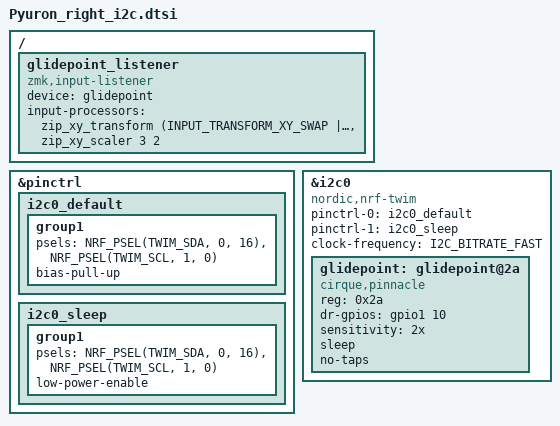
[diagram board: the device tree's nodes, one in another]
#include <input/processors.dtsi>
#include <dt-bindings/zmk/input_transform.h>
#include "Pyuron.dtsi"

&pinctrl {
    i2c0_default: i2c0_default {
        group1 {
            psels = <NRF_PSEL(TWIM_SDA, 0, 16)>,
                <NRF_PSEL(TWIM_SCL, 1, 0)>;
			bias-pull-up;
        };
    };

    i2c0_sleep: i2c0_sleep {
        group1 {
            psels = <NRF_PSEL(TWIM_SDA, 0, 16)>,
                <NRF_PSEL(TWIM_SCL, 1, 0)>;
            low-power-enable;
        };
    };
};

cirque_pinnacle_i2c: &i2c0 {
    compatible = "nordic,nrf-twim";
    pinctrl-0 = <&i2c0_default>;
    pinctrl-1 = <&i2c0_sleep>;
    pinctrl-names = "default", "sleep";
    clock-frequency = <I2C_BITRATE_FAST>;
};

// Enable custom i2c for the Right side

&cirque_pinnacle_i2c {
    status = "okay";

    glidepoint: glidepoint@2a {
        compatible = "cirque,pinnacle";
        reg = <0x2a>;
        status = "okay";
        // Pin marked as Serial in the Dilemma PCB (008/D0) is connected to the S pin in the TRRS footprint, 
        // so connecting this S pin to the DR pin in the Cirque, 
        // will make the MCU be notified when there is data ready in the cirque
        dr-gpios = <&gpio1 10 (GPIO_ACTIVE_HIGH)>;
        sensitivity = "2x";
        sleep; 
        no-taps;
    };
};

// Cirque Trackpad

&glidepoint {
	status = "okay";
};

// Cirque Trackpad, if the Left side is central, comment otherwise



// Cirque Trackpad, if the Right side is central, comment otherwise

 / {
 	glidepoint_listener: glidepoint_listener {
 		compatible = "zmk,input-listener";
 		status = "okay";
 		device = <&glidepoint>;
         input-processors = <&zip_xy_transform (INPUT_TRANSFORM_XY_SWAP | INPUT_TRANSFORM_X_INVERT | INPUT_TRANSFORM_Y_INVERT)>, <&zip_xy_scaler 3 2>;
 	};
 };
